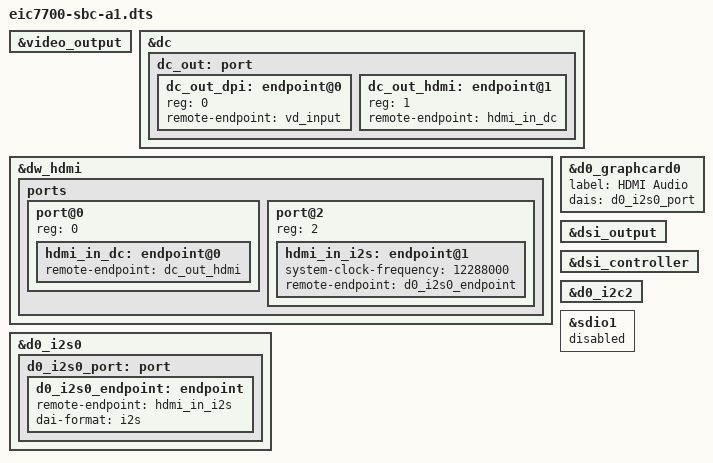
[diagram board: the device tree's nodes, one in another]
// SPDX-License-Identifier: GPL-2.0
/*
 * Device Tree file for Eswin EIC7700 SoC.
 *
 * Copyright 2024, Beijing ESWIN Computing Technology Co., Ltd.. All rights reserved.
 * SPDX-License-Identifier: GPL-2.0
 *
 * This program is free software: you can redistribute it and/or modify
 * it under the terms of the GNU General Public License as published by
 * the Free Software Foundation, version 2.
 *
 * This program is distributed in the hope that it will be useful,
 * but WITHOUT ANY WARRANTY; without even the implied warranty of
 * MERCHANTABILITY or FITNESS FOR A PARTICULAR PURPOSE.  See the
 * GNU General Public License for more details.
 *
 * You should have received a copy of the GNU General Public License
 * along with this program.  If not, see <https://www.gnu.org/licenses/>.
 */

#include "eic7700-sbc-a1.dtsi"


&video_output {
	status = "okay";
};

&dc {
	status = "okay";
	dc_out: port {
		#address-cells = <1>;
		#size-cells = <0>;
		dc_out_dpi: endpoint@0 {
			reg = <0>;
			remote-endpoint = <&vd_input>;
		};
		dc_out_hdmi: endpoint@1 {
			reg = <1>;
			remote-endpoint = <&hdmi_in_dc>;
		};
	};
};

&dw_hdmi {
        status = "okay";
        ports {
                #address-cells = <1>;
                #size-cells = <0>;
                port@0 {
                        reg = <0>;
                        hdmi_in_dc: endpoint@0 {
                                remote-endpoint = <&dc_out_hdmi>;
                        };
                };
                port@2 {
                        reg = <2>;
                        hdmi_in_i2s: endpoint@1 {
                                system-clock-frequency = <12288000>;
                                remote-endpoint = <&d0_i2s0_endpoint>;
                        };
                };
        };
};

&d0_i2s0 {
        status = "okay";
        d0_i2s0_port: port {
                d0_i2s0_endpoint: endpoint {
                        remote-endpoint = <&hdmi_in_i2s>;
                        dai-format = "i2s";
                };
        };
};

&d0_graphcard0 {
        status = "okay";
        label = "HDMI Audio";
        dais = <&d0_i2s0_port>;
};

&dsi_output {
    status = "okay";
};

&dsi_controller {
	status = "okay";
};

&d0_i2c2 {
	/* touch screen*/
	status = "okay";
};

&sdio1 {
        /* disable this port */
        status = "disabled";
};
